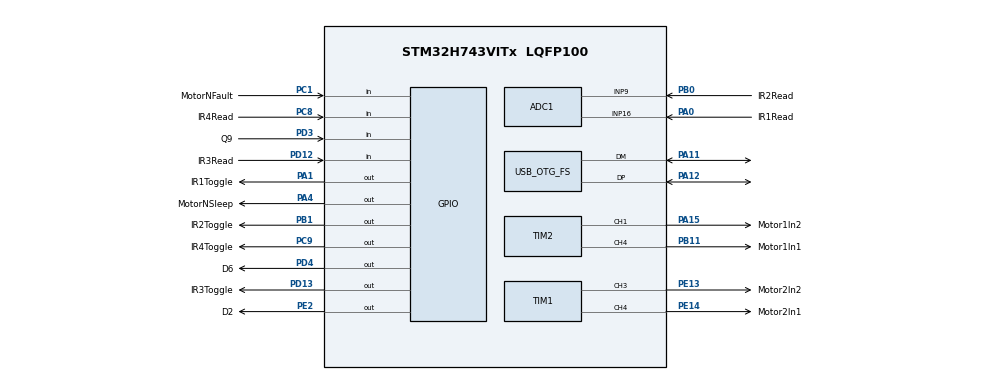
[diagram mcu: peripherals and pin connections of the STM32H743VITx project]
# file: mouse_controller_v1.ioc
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ADC1.Channel-0\#ChannelRegularConversion=ADC_CHANNEL_9
ADC1.NbrOfConversionFlag=1
ADC1.OffsetNumber-0\#ChannelRegularConversion=ADC_OFFSET_NONE
ADC1.OffsetSignedSaturation-0\#ChannelRegularConversion=DISABLE
ADC1.Rank-0\#ChannelRegularConversion=1
ADC1.SamplingTime-0\#ChannelRegularConversion=ADC_SAMPLETIME_1CYCLE_5
ADC1.master=1
CORTEX_M7.default_mode_Activation=1
FREERTOS.Tasks01=defaultTask,24,128,StartDefaultTask,Default,NULL,Dynamic,NULL,NULL
FREERTOS.configUSE_NEWLIB_REENTRANT=1
Mcu.Family=STM32H7
Mcu.Name=STM32H743VITx
Mcu.Package=LQFP100
NVIC.OTG_FS_IRQn=true\:5\:0\:false\:false\:true\:true\:false\:true\:true
NVIC.PriorityGroup=NVIC_PRIORITYGROUP_4
NVIC.TIM6_DAC_IRQn=true\:15\:0\:false\:false\:true\:false\:false\:true\:true
NVIC.TimeBase=TIM6_DAC_IRQn
NVIC.TimeBaseIP=TIM6
PA0.GPIO_Label=IR1Read
PA0.Mode=IN16-Single-Ended
PA0.Signal=ADC1_INP16
PA1.GPIO_Label=IR1Toggle
PA1.Signal=GPIO_Output
PA11.Mode=Device_Only
PA11.Signal=USB_OTG_FS_DM
PA12.Mode=Device_Only
PA12.Signal=USB_OTG_FS_DP
PA13\ (JTMS/SWDIO).Mode=Serial_Wire
PA13\ (JTMS/SWDIO).Signal=DEBUG_JTMS-SWDIO
PA14\ (JTCK/SWCLK).Mode=Serial_Wire
PA14\ (JTCK/SWCLK).Signal=DEBUG_JTCK-SWCLK
PA15\ (JTDI).GPIO_Label=Motor1In2
PA15\ (JTDI).Signal=S_TIM2_CH1_ETR
PA4.GPIO_Label=MotorNSleep
PA4.Signal=GPIO_Output
PB0.GPIO_Label=IR2Read
PB0.Signal=ADCx_INP9
PB1.GPIO_Label=IR2Toggle
PB1.Signal=GPIO_Output
PB11.GPIO_Label=Motor1In1
PB11.Signal=S_TIM2_CH4
PC1.GPIO_Label=MotorNFault
PC1.GPIO_PuPd=GPIO_PULLUP
PC1.Signal=GPIO_Input
PC8.GPIO_Label=IR4Read
PC8.Signal=GPIO_Input
PC9.GPIO_Label=IR4Toggle
PC9.Signal=GPIO_Output
PD12.GPIO_Label=IR3Read
PD12.Signal=GPIO_Input
PD13.GPIO_Label=IR3Toggle
PD13.Signal=GPIO_Output
PD3.GPIO_Label=Q9
PD3.Signal=GPIO_Input
PD4.GPIO_Label=D6
PD4.Signal=GPIO_Output
PE13.GPIO_Label=Motor2In2
PE13.Signal=S_TIM1_CH3
PE14.GPIO_Label=Motor2In1
PE14.Signal=S_TIM1_CH4
PE2.GPIO_Label=D2
PE2.Signal=GPIO_Output
ProjectManager.HeapSize=0x200
ProjectManager.StackSize=0x400
ProjectManager.TargetToolchain=STM32CubeIDE
RCC.ADCFreq_Value=129000000
RCC.APB1Freq_Value=64000000
RCC.APB2Freq_Value=64000000
RCC.APB3Freq_Value=64000000
RCC.APB4Freq_Value=64000000
RCC.CortexFreq_Value=64000000
RCC.HCLKFreq_Value=64000000
RCC.PLLSourceVirtualString=RCC_PLLSOURCE_HSI
RCC.SYSCLKFreq_VALUE=64000000
RCC.USBFreq_Value=129000000
SH.ADCx_INP9.0=ADC1_INP9,IN9-Single-Ended
SH.S_TIM1_CH3.0=TIM1_CH3,PWM Generation3 CH3
SH.S_TIM1_CH4.0=TIM1_CH4,PWM Generation4 CH4
SH.S_TIM2_CH1_ETR.0=TIM2_CH1,PWM Generation1 CH1
SH.S_TIM2_CH4.0=TIM2_CH4,PWM Generation4 CH4
TIM1.Channel-PWM\ Generation3\ CH3=TIM_CHANNEL_3
TIM1.Channel-PWM\ Generation4\ CH4=TIM_CHANNEL_4
TIM2.Channel-PWM\ Generation1\ CH1=TIM_CHANNEL_1
TIM2.Channel-PWM\ Generation4\ CH4=TIM_CHANNEL_4
USB_DEVICE.CLASS_NAME_FS=CDC
USB_DEVICE.VirtualMode-CDC_FS=Cdc
USB_DEVICE.VirtualModeFS=Cdc_FS
USB_OTG_FS.VirtualMode=Device_Only
VP_FREERTOS_VS_CMSIS_V2.Mode=CMSIS_V2
VP_MEMORYMAP_VS_MEMORYMAP.Mode=CurAppReg
VP_SYS_VS_tim6.Mode=TIM6
VP_TIM1_VS_ClockSourceINT.Mode=Internal
VP_TIM2_VS_ClockSourceINT.Mode=Internal
VP_USB_DEVICE_VS_USB_DEVICE_CDC_FS.Mode=CDC_FS
board=custom

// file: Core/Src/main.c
/* USER CODE BEGIN Header */
/**
  ******************************************************************************
  * @file           : main.c
  * @brief          : Main program body
  ******************************************************************************
  * @attention
  *
  * Copyright (c) 2026 STMicroelectronics.
  * All rights reserved.
  *
  * This software is licensed under terms that can be found in the LICENSE file
  * in the root directory of this software component.
  * If no LICENSE file comes with this software, it is provided AS-IS.
  *
  ******************************************************************************
  */
/* USER CODE END Header */
#include "main.h"
#include "FreeRTOS.h"
#include "cmsis_os2.h"
#include "usb_device.h"

/* USER CODE BEGIN Includes */
#include "app_entry.h"
/* USER CODE END Includes */

ADC_HandleTypeDef hadc1;

TIM_HandleTypeDef htim1;
TIM_HandleTypeDef htim2;

/* Definitions for defaultTask */
osThreadId_t defaultTaskHandle;
const osThreadAttr_t defaultTask_attributes = {
  .name = "defaultTask",
  .stack_size = 128 * 4,
  .priority = (osPriority_t) osPriorityNormal,
};

void SystemClock_Config(void);
static void MPU_Config(void);
static void MX_GPIO_Init(void);
static void MX_ADC1_Init(void);
static void MX_TIM1_Init(void);
static void MX_TIM2_Init(void);
void StartDefaultTask(void *argument);

int main(void)
{

  /* MPU Configuration--------------------------------------------------------*/
  MPU_Config();

  /* MCU Configuration--------------------------------------------------------*/

  /* Reset of all peripherals, Initializes the Flash interface and the Systick. */
  HAL_Init();

  /* Configure the system clock */
  SystemClock_Config();

  /* Initialize all configured peripherals */
  MX_GPIO_Init();
  MX_ADC1_Init();
  MX_TIM1_Init();
  MX_TIM2_Init();

  /* Init scheduler */
  osKernelInitialize();

  /* Create the thread(s) */
  /* creation of defaultTask */
  defaultTaskHandle = osThreadNew(StartDefaultTask, NULL, &defaultTask_attributes);

  /* Start scheduler */
  osKernelStart();

  /* We should never get here as control is now taken by the scheduler */

  /* Infinite loop */
  while (1)
  {

  }
}

void SystemClock_Config(void)
{
  RCC_OscInitTypeDef RCC_OscInitStruct = {0};
  RCC_ClkInitTypeDef RCC_ClkInitStruct = {0};

  /** Supply configuration update enable
  */
  HAL_PWREx_ConfigSupply(PWR_LDO_SUPPLY);

  /** Configure the main internal regulator output voltage
  */
  __HAL_PWR_VOLTAGESCALING_CONFIG(PWR_REGULATOR_VOLTAGE_SCALE3);

  while(!__HAL_PWR_GET_FLAG(PWR_FLAG_VOSRDY)) {}

  /** Initializes the RCC Oscillators according to the specified parameters
  * in the RCC_OscInitTypeDef structure.
  */
  RCC_OscInitStruct.OscillatorType = RCC_OSCILLATORTYPE_HSI;
  RCC_OscInitStruct.HSIState = RCC_HSI_DIV1;
  RCC_OscInitStruct.HSICalibrationValue = RCC_HSICALIBRATION_DEFAULT;
  RCC_OscInitStruct.PLL.PLLState = RCC_PLL_ON;
  RCC_OscInitStruct.PLL.PLLSource = RCC_PLLSOURCE_HSI;
  RCC_OscInitStruct.PLL.PLLM = 32;
  RCC_OscInitStruct.PLL.PLLN = 129;
  RCC_OscInitStruct.PLL.PLLP = 2;
  RCC_OscInitStruct.PLL.PLLQ = 2;
  RCC_OscInitStruct.PLL.PLLR = 2;
  RCC_OscInitStruct.PLL.PLLRGE = RCC_PLL1VCIRANGE_1;
  RCC_OscInitStruct.PLL.PLLVCOSEL = RCC_PLL1VCOWIDE;
  RCC_OscInitStruct.PLL.PLLFRACN = 0;
  if (HAL_RCC_OscConfig(&RCC_OscInitStruct) != HAL_OK)
  {
    Error_Handler();
  }

  /** Initializes the CPU, AHB and APB buses clocks
  */
  RCC_ClkInitStruct.ClockType = RCC_CLOCKTYPE_HCLK|RCC_CLOCKTYPE_SYSCLK
                              |RCC_CLOCKTYPE_PCLK1|RCC_CLOCKTYPE_PCLK2
                              |RCC_CLOCKTYPE_D3PCLK1|RCC_CLOCKTYPE_D1PCLK1;
  RCC_ClkInitStruct.SYSCLKSource = RCC_SYSCLKSOURCE_HSI;
  RCC_ClkInitStruct.SYSCLKDivider = RCC_SYSCLK_DIV1;
  RCC_ClkInitStruct.AHBCLKDivider = RCC_HCLK_DIV1;
  RCC_ClkInitStruct.APB3CLKDivider = RCC_APB3_DIV1;
  RCC_ClkInitStruct.APB1CLKDivider = RCC_APB1_DIV1;
  RCC_ClkInitStruct.APB2CLKDivider = RCC_APB2_DIV1;
  RCC_ClkInitStruct.APB4CLKDivider = RCC_APB4_DIV1;

  if (HAL_RCC_ClockConfig(&RCC_ClkInitStruct, FLASH_LATENCY_1) != HAL_OK)
  {
    Error_Handler();
  }
}

static void MX_ADC1_Init(void)
{

  ADC_MultiModeTypeDef multimode = {0};
  ADC_ChannelConfTypeDef sConfig = {0};

  /** Common config
  */
  hadc1.Instance = ADC1;
  hadc1.Init.ClockPrescaler = ADC_CLOCK_ASYNC_DIV4;
  hadc1.Init.Resolution = ADC_RESOLUTION_16B;
  hadc1.Init.ScanConvMode = ADC_SCAN_DISABLE;
  hadc1.Init.EOCSelection = ADC_EOC_SINGLE_CONV;
  hadc1.Init.LowPowerAutoWait = DISABLE;
  hadc1.Init.ContinuousConvMode = DISABLE;
  hadc1.Init.NbrOfConversion = 1;
  hadc1.Init.DiscontinuousConvMode = DISABLE;
  hadc1.Init.ExternalTrigConv = ADC_SOFTWARE_START;
  hadc1.Init.ExternalTrigConvEdge = ADC_EXTERNALTRIGCONVEDGE_NONE;
  hadc1.Init.ConversionDataManagement = ADC_CONVERSIONDATA_DR;
  hadc1.Init.Overrun = ADC_OVR_DATA_PRESERVED;
  hadc1.Init.LeftBitShift = ADC_LEFTBITSHIFT_NONE;
  hadc1.Init.OversamplingMode = DISABLE;
  hadc1.Init.Oversampling.Ratio = 1;
  if (HAL_ADC_Init(&hadc1) != HAL_OK)
  {
    Error_Handler();
  }

  /** Configure the ADC multi-mode
  */
  multimode.Mode = ADC_MODE_INDEPENDENT;
  if (HAL_ADCEx_MultiModeConfigChannel(&hadc1, &multimode) != HAL_OK)
  {
    Error_Handler();
  }

  /** Configure Regular Channel
  */
  sConfig.Channel = ADC_CHANNEL_9;
  sConfig.Rank = ADC_REGULAR_RANK_1;
  sConfig.SamplingTime = ADC_SAMPLETIME_1CYCLE_5;
  sConfig.SingleDiff = ADC_SINGLE_ENDED;
  sConfig.OffsetNumber = ADC_OFFSET_NONE;
  sConfig.Offset = 0;
  sConfig.OffsetSignedSaturation = DISABLE;
  if (HAL_ADC_ConfigChannel(&hadc1, &sConfig) != HAL_OK)
  {
    Error_Handler();
  }

}

static void MX_TIM1_Init(void)
{

  TIM_ClockConfigTypeDef sClockSourceConfig = {0};
  TIM_MasterConfigTypeDef sMasterConfig = {0};
  TIM_OC_InitTypeDef sConfigOC = {0};
  TIM_BreakDeadTimeConfigTypeDef sBreakDeadTimeConfig = {0};

  htim1.Instance = TIM1;
  htim1.Init.Prescaler = 0;
  htim1.Init.CounterMode = TIM_COUNTERMODE_UP;
  htim1.Init.Period = 65535;
  htim1.Init.ClockDivision = TIM_CLOCKDIVISION_DIV1;
  htim1.Init.RepetitionCounter = 0;
  htim1.Init.AutoReloadPreload = TIM_AUTORELOAD_PRELOAD_DISABLE;
  if (HAL_TIM_Base_Init(&htim1) != HAL_OK)
  {
    Error_Handler();
  }
  sClockSourceConfig.ClockSource = TIM_CLOCKSOURCE_INTERNAL;
  if (HAL_TIM_ConfigClockSource(&htim1, &sClockSourceConfig) != HAL_OK)
  {
    Error_Handler();
  }
  if (HAL_TIM_PWM_Init(&htim1) != HAL_OK)
  {
    Error_Handler();
  }
  sMasterConfig.MasterOutputTrigger = TIM_TRGO_RESET;
  sMasterConfig.MasterOutputTrigger2 = TIM_TRGO2_RESET;
  sMasterConfig.MasterSlaveMode = TIM_MASTERSLAVEMODE_DISABLE;
  if (HAL_TIMEx_MasterConfigSynchronization(&htim1, &sMasterConfig) != HAL_OK)
  {
    Error_Handler();
  }
  sConfigOC.OCMode = TIM_OCMODE_PWM1;
  sConfigOC.Pulse = 0;
  sConfigOC.OCPolarity = TIM_OCPOLARITY_HIGH;
  sConfigOC.OCNPolarity = TIM_OCNPOLARITY_HIGH;
  sConfigOC.OCFastMode = TIM_OCFAST_DISABLE;
  sConfigOC.OCIdleState = TIM_OCIDLESTATE_RESET;
  sConfigOC.OCNIdleState = TIM_OCNIDLESTATE_RESET;
  if (HAL_TIM_PWM_ConfigChannel(&htim1, &sConfigOC, TIM_CHANNEL_3) != HAL_OK)
  {
    Error_Handler();
  }
  if (HAL_TIM_PWM_ConfigChannel(&htim1, &sConfigOC, TIM_CHANNEL_4) != HAL_OK)
  {
    Error_Handler();
  }
  sBreakDeadTimeConfig.OffStateRunMode = TIM_OSSR_DISABLE;
  sBreakDeadTimeConfig.OffStateIDLEMode = TIM_OSSI_DISABLE;
  sBreakDeadTimeConfig.LockLevel = TIM_LOCKLEVEL_OFF;
  sBreakDeadTimeConfig.DeadTime = 0;
  sBreakDeadTimeConfig.BreakState = TIM_BREAK_DISABLE;
  sBreakDeadTimeConfig.BreakPolarity = TIM_BREAKPOLARITY_HIGH;
  sBreakDeadTimeConfig.BreakFilter = 0;
  sBreakDeadTimeConfig.Break2State = TIM_BREAK2_DISABLE;
  sBreakDeadTimeConfig.Break2Polarity = TIM_BREAK2POLARITY_HIGH;
  sBreakDeadTimeConfig.Break2Filter = 0;
  sBreakDeadTimeConfig.AutomaticOutput = TIM_AUTOMATICOUTPUT_DISABLE;
  if (HAL_TIMEx_ConfigBreakDeadTime(&htim1, &sBreakDeadTimeConfig) != HAL_OK)
  {
    Error_Handler();
  }
  HAL_TIM_MspPostInit(&htim1);

}

static void MX_TIM2_Init(void)
{

  TIM_ClockConfigTypeDef sClockSourceConfig = {0};
  TIM_MasterConfigTypeDef sMasterConfig = {0};
  TIM_OC_InitTypeDef sConfigOC = {0};

  htim2.Instance = TIM2;
  htim2.Init.Prescaler = 0;
  htim2.Init.CounterMode = TIM_COUNTERMODE_UP;
  htim2.Init.Period = 4294967295;
  htim2.Init.ClockDivision = TIM_CLOCKDIVISION_DIV1;
  htim2.Init.AutoReloadPreload = TIM_AUTORELOAD_PRELOAD_DISABLE;
  if (HAL_TIM_Base_Init(&htim2) != HAL_OK)
  {
    Error_Handler();
  }
  sClockSourceConfig.ClockSource = TIM_CLOCKSOURCE_INTERNAL;
  if (HAL_TIM_ConfigClockSource(&htim2, &sClockSourceConfig) != HAL_OK)
  {
    Error_Handler();
  }
  if (HAL_TIM_PWM_Init(&htim2) != HAL_OK)
  {
    Error_Handler();
  }
  sMasterConfig.MasterOutputTrigger = TIM_TRGO_RESET;
  sMasterConfig.MasterSlaveMode = TIM_MASTERSLAVEMODE_DISABLE;
  if (HAL_TIMEx_MasterConfigSynchronization(&htim2, &sMasterConfig) != HAL_OK)
  {
    Error_Handler();
  }
  sConfigOC.OCMode = TIM_OCMODE_PWM1;
  sConfigOC.Pulse = 0;
  sConfigOC.OCPolarity = TIM_OCPOLARITY_HIGH;
  sConfigOC.OCFastMode = TIM_OCFAST_DISABLE;
  if (HAL_TIM_PWM_ConfigChannel(&htim2, &sConfigOC, TIM_CHANNEL_1) != HAL_OK)
  {
    Error_Handler();
  }
  if (HAL_TIM_PWM_ConfigChannel(&htim2, &sConfigOC, TIM_CHANNEL_4) != HAL_OK)
  {
    Error_Handler();
  }
  HAL_TIM_MspPostInit(&htim2);

}

static void MX_GPIO_Init(void)
{
  GPIO_InitTypeDef GPIO_InitStruct = {0};

  /* GPIO Ports Clock Enable */
  __HAL_RCC_GPIOE_CLK_ENABLE();
  __HAL_RCC_GPIOC_CLK_ENABLE();
  __HAL_RCC_GPIOA_CLK_ENABLE();
  __HAL_RCC_GPIOB_CLK_ENABLE();
  __HAL_RCC_GPIOD_CLK_ENABLE();

  /*Configure GPIO pin Output Level */
  HAL_GPIO_WritePin(D2_GPIO_Port, D2_Pin, GPIO_PIN_RESET);

  /*Configure GPIO pin Output Level */
  HAL_GPIO_WritePin(GPIOA, IR1Toggle_Pin|MotorNSleep_Pin, GPIO_PIN_RESET);

  /*Configure GPIO pin Output Level */
  HAL_GPIO_WritePin(IR2Toggle_GPIO_Port, IR2Toggle_Pin, GPIO_PIN_RESET);

  /*Configure GPIO pin Output Level */
  HAL_GPIO_WritePin(GPIOD, IR3Toggle_Pin|D6_Pin, GPIO_PIN_RESET);

  /*Configure GPIO pin Output Level */
  HAL_GPIO_WritePin(IR4Toggle_GPIO_Port, IR4Toggle_Pin, GPIO_PIN_RESET);

  /*Configure GPIO pin : D2_Pin */
  GPIO_InitStruct.Pin = D2_Pin;
  GPIO_InitStruct.Mode = GPIO_MODE_OUTPUT_PP;
  GPIO_InitStruct.Pull = GPIO_NOPULL;
  GPIO_InitStruct.Speed = GPIO_SPEED_FREQ_LOW;
  HAL_GPIO_Init(D2_GPIO_Port, &GPIO_InitStruct);

  /*Configure GPIO pin : MotorNFault_Pin */
  GPIO_InitStruct.Pin = MotorNFault_Pin;
  GPIO_InitStruct.Mode = GPIO_MODE_INPUT;
  GPIO_InitStruct.Pull = GPIO_PULLUP;
  HAL_GPIO_Init(MotorNFault_GPIO_Port, &GPIO_InitStruct);

  /*Configure GPIO pins : IR1Toggle_Pin MotorNSleep_Pin */
  GPIO_InitStruct.Pin = IR1Toggle_Pin|MotorNSleep_Pin;
  GPIO_InitStruct.Mode = GPIO_MODE_OUTPUT_PP;
  GPIO_InitStruct.Pull = GPIO_NOPULL;
  GPIO_InitStruct.Speed = GPIO_SPEED_FREQ_LOW;
  HAL_GPIO_Init(GPIOA, &GPIO_InitStruct);

  /*Configure GPIO pin : IR2Toggle_Pin */
  GPIO_InitStruct.Pin = IR2Toggle_Pin;
  GPIO_InitStruct.Mode = GPIO_MODE_OUTPUT_PP;
  GPIO_InitStruct.Pull = GPIO_NOPULL;
  GPIO_InitStruct.Speed = GPIO_SPEED_FREQ_LOW;
  HAL_GPIO_Init(IR2Toggle_GPIO_Port, &GPIO_InitStruct);

  /*Configure GPIO pins : IR3Read_Pin Q9_Pin */
  GPIO_InitStruct.Pin = IR3Read_Pin|Q9_Pin;
  GPIO_InitStruct.Mode = GPIO_MODE_INPUT;
  GPIO_InitStruct.Pull = GPIO_NOPULL;
  HAL_GPIO_Init(GPIOD, &GPIO_InitStruct);

  /*Configure GPIO pins : IR3Toggle_Pin D6_Pin */
  GPIO_InitStruct.Pin = IR3Toggle_Pin|D6_Pin;
  GPIO_InitStruct.Mode = GPIO_MODE_OUTPUT_PP;
  GPIO_InitStruct.Pull = GPIO_NOPULL;
  GPIO_InitStruct.Speed = GPIO_SPEED_FREQ_LOW;
  HAL_GPIO_Init(GPIOD, &GPIO_InitStruct);

  /*Configure GPIO pin : IR4Read_Pin */
  GPIO_InitStruct.Pin = IR4Read_Pin;
  GPIO_InitStruct.Mode = GPIO_MODE_INPUT;
  GPIO_InitStruct.Pull = GPIO_NOPULL;
  HAL_GPIO_Init(IR4Read_GPIO_Port, &GPIO_InitStruct);

  /*Configure GPIO pin : IR4Toggle_Pin */
  GPIO_InitStruct.Pin = IR4Toggle_Pin;
  GPIO_InitStruct.Mode = GPIO_MODE_OUTPUT_PP;
  GPIO_InitStruct.Pull = GPIO_NOPULL;
  GPIO_InitStruct.Speed = GPIO_SPEED_FREQ_LOW;
  HAL_GPIO_Init(IR4Toggle_GPIO_Port, &GPIO_InitStruct);

  /*AnalogSwitch Config */
  HAL_SYSCFG_AnalogSwitchConfig(SYSCFG_SWITCH_PA1, SYSCFG_SWITCH_PA1_CLOSE);

}

void StartDefaultTask(void *argument)
{
  /* init code for USB_DEVICE */
//  MX_USB_DEVICE_Init();
  /* USER CODE BEGIN 5 */

	// Leave main.c and move to app_entry.c
	app_main();
	// The infinite loop in app_main() will prevent any further code execution

  /* Infinite loop */
  for(;;)
  {
	  osDelay(1);
  }
  /* USER CODE END 5 */
}

 /* MPU Configuration */

void MPU_Config(void)
{
  MPU_Region_InitTypeDef MPU_InitStruct = {0};

  /* Disables the MPU */
  HAL_MPU_Disable();

  /** Initializes and configures the Region and the memory to be protected
  */
  MPU_InitStruct.Enable = MPU_REGION_ENABLE;
  MPU_InitStruct.Number = MPU_REGION_NUMBER0;
  MPU_InitStruct.BaseAddress = 0x0;
  MPU_InitStruct.Size = MPU_REGION_SIZE_4GB;
  MPU_InitStruct.SubRegionDisable = 0x87;
  MPU_InitStruct.TypeExtField = MPU_TEX_LEVEL0;
  MPU_InitStruct.AccessPermission = MPU_REGION_NO_ACCESS;
  MPU_InitStruct.DisableExec = MPU_INSTRUCTION_ACCESS_DISABLE;
  MPU_InitStruct.IsShareable = MPU_ACCESS_SHAREABLE;
  MPU_InitStruct.IsCacheable = MPU_ACCESS_NOT_CACHEABLE;
  MPU_InitStruct.IsBufferable = MPU_ACCESS_NOT_BUFFERABLE;

  HAL_MPU_ConfigRegion(&MPU_InitStruct);
  /* Enables the MPU */
  HAL_MPU_Enable(MPU_PRIVILEGED_DEFAULT);

}

void HAL_TIM_PeriodElapsedCallback(TIM_HandleTypeDef *htim)
{
  if (htim->Instance == TIM6)
  {
    HAL_IncTick();
  }
}

void Error_Handler(void)
{
  __disable_irq();
  while (1)
  {
  }
}
